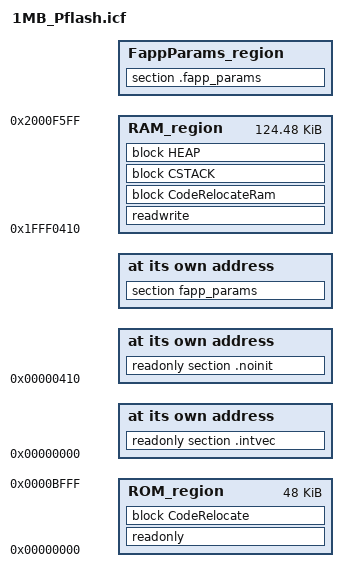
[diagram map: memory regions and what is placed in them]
/*###ICF### Section handled by ICF editor, don't touch! ****/
/*-Editor annotation file-*/
/* IcfEditorFile="$TOOLKIT_DIR$\config\ide\IcfEditor\cortex_v1_0.xml" */
/*-Specials-*/
define symbol __ICFEDIT_intvec_start__ = 0x00000000;
/*-Memory Regions-*/
define symbol __ICFEDIT_region_ROM_start__ = 0x00000000;
define symbol __ICFEDIT_region_ROM_end__   = 0x00100000;
define symbol Fapp_Size_Reserved   = 0x0000C000; // First 48 KBs of FLASH are reserved by Bootloader.
define symbol __ICFEDIT_region_RAM_start__ = 0x1FFF0410;
define symbol __ICFEDIT_region_RAM_end__   = 0x20010000;
/*-Sizes-*/
define symbol __ICFEDIT_size_cstack__ = 0xA00; //2.5KB
define symbol __ICFEDIT_size_heap__   = 0x000;  
/**** End of ICF editor section. ###ICF###*/

define symbol FappParams_start__= __ICFEDIT_region_ROM_end__ - (4*0x400); //FAPP
define symbol FappParams_end__  = __ICFEDIT_region_ROM_end__-1; //FAPP

define exported symbol __VECTOR_TABLE = 0x00000000;
define exported symbol __VECTOR_RAM = 0x1fff0000;


define exported symbol __BOOT_STACK_ADDRESS = __ICFEDIT_region_RAM_end__ - 8;	//0x2000FFF8;

define symbol __code_start__ = 0x00000410;

/* The memory space denoting the maximum possible amount of addressable memory */
define memory mem with size = 4G;

define region ROM_region   = mem:[from __ICFEDIT_region_ROM_start__   to Fapp_Size_Reserved-1];
define region RAM_region   = mem:[from __ICFEDIT_region_RAM_start__   to __ICFEDIT_region_RAM_end__-1-__ICFEDIT_size_cstack__];
define region FappParams_region = mem:[from FappParams_start__ to FappParams_end__]; //FAPP

define block CSTACK    with alignment = 8, size = __ICFEDIT_size_cstack__   { };
define block HEAP      with alignment = 8, size = __ICFEDIT_size_heap__     { };

initialize manually { readwrite };
initialize manually { section .data};
initialize manually { section .textrw };
do not initialize  { section .noinit };

define block CodeRelocate { section .textrw_init };
define block CodeRelocateRam { section .textrw };

place at address mem:__ICFEDIT_intvec_start__ { readonly section .intvec };
place at address mem:__code_start__ { readonly section .noinit };
place at address mem:FappParams_start__ { section fapp_params }; //APP

place in ROM_region   { readonly, block CodeRelocate};

place in RAM_region   { readwrite, block CodeRelocateRam,
                        block CSTACK, block HEAP };

place in FappParams_region
                      {section .fapp_params};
